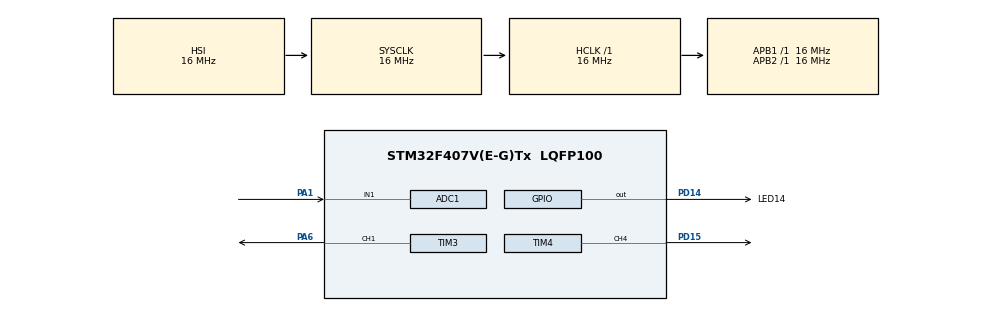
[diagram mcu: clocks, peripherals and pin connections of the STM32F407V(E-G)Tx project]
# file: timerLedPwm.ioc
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Mcu.Family=STM32F4
RCC.CortexFreq_Value=16000000
ADC1.Rank-0\#ChannelRegularConversion=1
SH.S_TIM4_CH4.0=TIM4_CH4,PWM Generation4 CH4
ProjectManager.StackSize=0x400
TIM3.Pulse-PWM\ Generation1\ CH1=500
ProjectManager.TargetToolchain=STM32CubeIDE
TIM3.Period=999
TIM4.Prescaler=31999
RCC.LSE_VALUE=32768
PA1.Signal=ADCx_IN1
RCC.AHBFreq_Value=16000000
TIM3.Channel-PWM\ Generation1\ CH1=TIM_CHANNEL_1
ADC1.Channel-0\#ChannelRegularConversion=ADC_CHANNEL_1
RCC.HSE_VALUE=25000000
board=custom
RCC.VCOOutputFreq_Value=192000000
TIM4.Pulse-PWM\ Generation4\ CH4=500
NVIC.TIM3_IRQn=true\:0\:0\:false\:false\:true\:true\:true
RCC.APB2Freq_Value=16000000
TIM3.Prescaler=7
PD14.GPIO_Label=LED14
SH.S_TIM3_CH1.0=TIM3_CH1,PWM Generation1 CH1
TIM4.Period=999
Mcu.Name=STM32F407V(E-G)Tx
ADC1.SamplingTime-0\#ChannelRegularConversion=ADC_SAMPLETIME_3CYCLES
PD14.Signal=GPIO_Output
RCC.SYSCLKFreq_VALUE=16000000
Mcu.Package=LQFP100
PA6.Signal=S_TIM3_CH1
ADC1.master=1
ProjectManager.HeapSize=0x200
RCC.HSI_VALUE=16000000
NVIC.PriorityGroup=NVIC_PRIORITYGROUP_4
ADC1.NbrOfConversionFlag=1
SH.ADCx_IN1.0=ADC1_IN1,IN1
TIM4.Channel-PWM\ Generation4\ CH4=TIM_CHANNEL_4
NVIC.TIM4_IRQn=true\:0\:0\:false\:false\:true\:true\:true
RCC.APB1Freq_Value=16000000
PD15.Signal=S_TIM4_CH4

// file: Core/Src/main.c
/* USER CODE BEGIN Header */
/**
  ******************************************************************************
  * @file           : main.c
  * @brief          : Main program body
  ******************************************************************************
  * @attention
  *
  * <h2><center>&copy; Copyright (c) 2021 STMicroelectronics.
  * All rights reserved.</center></h2>
  *
  * This software component is licensed by ST under BSD 3-Clause license,
  * the "License"; You may not use this file except in compliance with the
  * License. You may obtain a copy of the License at:
  *                        opensource.org/licenses/BSD-3-Clause
  *
  ******************************************************************************
  */
/* USER CODE END Header */
#include "main.h"

ADC_HandleTypeDef hadc1;

TIM_HandleTypeDef htim3;
TIM_HandleTypeDef htim4;

void SystemClock_Config(void);
static void MX_GPIO_Init(void);
static void MX_TIM3_Init(void);
static void MX_TIM4_Init(void);
static void MX_ADC1_Init(void);

int main(void)
{

  /* MCU Configuration--------------------------------------------------------*/

  /* Reset of all peripherals, Initializes the Flash interface and the Systick. */
  HAL_Init();

  /* Configure the system clock */
  SystemClock_Config();

  /* Initialize all configured peripherals */
  MX_GPIO_Init();
  MX_TIM3_Init();
  MX_TIM4_Init();
  MX_ADC1_Init();
  /* USER CODE BEGIN 2 */
  HAL_TIM_PWM_Start_IT(&htim4, TIM_CHANNEL_4);
  /* USER CODE END 2 */

  /* Infinite loop */
  /* USER CODE BEGIN WHILE */
  while (1)
  {

   TIM4 -> CCR4 = 250; // 0.5 saniye yandı
   //Channel4 kullanıldığı için CCR4 kullanıldı

    /* USER CODE END WHILE */

  }
}

void SystemClock_Config(void)
{
  RCC_OscInitTypeDef RCC_OscInitStruct = {0};
  RCC_ClkInitTypeDef RCC_ClkInitStruct = {0};

  /** Configure the main internal regulator output voltage
  */
  __HAL_RCC_PWR_CLK_ENABLE();
  __HAL_PWR_VOLTAGESCALING_CONFIG(PWR_REGULATOR_VOLTAGE_SCALE1);
  /** Initializes the RCC Oscillators according to the specified parameters
  * in the RCC_OscInitTypeDef structure.
  */
  RCC_OscInitStruct.OscillatorType = RCC_OSCILLATORTYPE_HSI;
  RCC_OscInitStruct.HSIState = RCC_HSI_ON;
  RCC_OscInitStruct.HSICalibrationValue = RCC_HSICALIBRATION_DEFAULT;
  RCC_OscInitStruct.PLL.PLLState = RCC_PLL_NONE;
  if (HAL_RCC_OscConfig(&RCC_OscInitStruct) != HAL_OK)
  {
    Error_Handler();
  }
  /** Initializes the CPU, AHB and APB buses clocks
  */
  RCC_ClkInitStruct.ClockType = RCC_CLOCKTYPE_HCLK|RCC_CLOCKTYPE_SYSCLK
                              |RCC_CLOCKTYPE_PCLK1|RCC_CLOCKTYPE_PCLK2;
  RCC_ClkInitStruct.SYSCLKSource = RCC_SYSCLKSOURCE_HSI;
  RCC_ClkInitStruct.AHBCLKDivider = RCC_SYSCLK_DIV1;
  RCC_ClkInitStruct.APB1CLKDivider = RCC_HCLK_DIV1;
  RCC_ClkInitStruct.APB2CLKDivider = RCC_HCLK_DIV1;

  if (HAL_RCC_ClockConfig(&RCC_ClkInitStruct, FLASH_LATENCY_0) != HAL_OK)
  {
    Error_Handler();
  }
}

static void MX_ADC1_Init(void)
{

  ADC_ChannelConfTypeDef sConfig = {0};

  /** Configure the global features of the ADC (Clock, Resolution, Data Alignment and number of conversion)
  */
  hadc1.Instance = ADC1;
  hadc1.Init.ClockPrescaler = ADC_CLOCK_SYNC_PCLK_DIV2;
  hadc1.Init.Resolution = ADC_RESOLUTION_12B;
  hadc1.Init.ScanConvMode = DISABLE;
  hadc1.Init.ContinuousConvMode = DISABLE;
  hadc1.Init.DiscontinuousConvMode = DISABLE;
  hadc1.Init.ExternalTrigConvEdge = ADC_EXTERNALTRIGCONVEDGE_NONE;
  hadc1.Init.ExternalTrigConv = ADC_SOFTWARE_START;
  hadc1.Init.DataAlign = ADC_DATAALIGN_RIGHT;
  hadc1.Init.NbrOfConversion = 1;
  hadc1.Init.DMAContinuousRequests = DISABLE;
  hadc1.Init.EOCSelection = ADC_EOC_SINGLE_CONV;
  if (HAL_ADC_Init(&hadc1) != HAL_OK)
  {
    Error_Handler();
  }
  /** Configure for the selected ADC regular channel its corresponding rank in the sequencer and its sample time.
  */
  sConfig.Channel = ADC_CHANNEL_1;
  sConfig.Rank = 1;
  sConfig.SamplingTime = ADC_SAMPLETIME_3CYCLES;
  if (HAL_ADC_ConfigChannel(&hadc1, &sConfig) != HAL_OK)
  {
    Error_Handler();
  }

}

static void MX_TIM3_Init(void)
{

  TIM_MasterConfigTypeDef sMasterConfig = {0};
  TIM_OC_InitTypeDef sConfigOC = {0};

  htim3.Instance = TIM3;
  htim3.Init.Prescaler = 7;
  htim3.Init.CounterMode = TIM_COUNTERMODE_UP;
  htim3.Init.Period = 999;
  htim3.Init.ClockDivision = TIM_CLOCKDIVISION_DIV1;
  htim3.Init.AutoReloadPreload = TIM_AUTORELOAD_PRELOAD_DISABLE;
  if (HAL_TIM_PWM_Init(&htim3) != HAL_OK)
  {
    Error_Handler();
  }
  sMasterConfig.MasterOutputTrigger = TIM_TRGO_RESET;
  sMasterConfig.MasterSlaveMode = TIM_MASTERSLAVEMODE_DISABLE;
  if (HAL_TIMEx_MasterConfigSynchronization(&htim3, &sMasterConfig) != HAL_OK)
  {
    Error_Handler();
  }
  sConfigOC.OCMode = TIM_OCMODE_PWM1;
  sConfigOC.Pulse = 500;
  sConfigOC.OCPolarity = TIM_OCPOLARITY_HIGH;
  sConfigOC.OCFastMode = TIM_OCFAST_DISABLE;
  if (HAL_TIM_PWM_ConfigChannel(&htim3, &sConfigOC, TIM_CHANNEL_1) != HAL_OK)
  {
    Error_Handler();
  }
  HAL_TIM_MspPostInit(&htim3);

}

static void MX_TIM4_Init(void)
{

  TIM_MasterConfigTypeDef sMasterConfig = {0};
  TIM_OC_InitTypeDef sConfigOC = {0};

  htim4.Instance = TIM4;
  htim4.Init.Prescaler = 31999;
  htim4.Init.CounterMode = TIM_COUNTERMODE_UP;
  htim4.Init.Period = 999;
  htim4.Init.ClockDivision = TIM_CLOCKDIVISION_DIV1;
  htim4.Init.AutoReloadPreload = TIM_AUTORELOAD_PRELOAD_DISABLE;
  if (HAL_TIM_PWM_Init(&htim4) != HAL_OK)
  {
    Error_Handler();
  }
  sMasterConfig.MasterOutputTrigger = TIM_TRGO_RESET;
  sMasterConfig.MasterSlaveMode = TIM_MASTERSLAVEMODE_DISABLE;
  if (HAL_TIMEx_MasterConfigSynchronization(&htim4, &sMasterConfig) != HAL_OK)
  {
    Error_Handler();
  }
  sConfigOC.OCMode = TIM_OCMODE_PWM1;
  sConfigOC.Pulse = 500;
  sConfigOC.OCPolarity = TIM_OCPOLARITY_HIGH;
  sConfigOC.OCFastMode = TIM_OCFAST_DISABLE;
  if (HAL_TIM_PWM_ConfigChannel(&htim4, &sConfigOC, TIM_CHANNEL_4) != HAL_OK)
  {
    Error_Handler();
  }
  HAL_TIM_MspPostInit(&htim4);

}

static void MX_GPIO_Init(void)
{
  GPIO_InitTypeDef GPIO_InitStruct = {0};

  /* GPIO Ports Clock Enable */
  __HAL_RCC_GPIOA_CLK_ENABLE();
  __HAL_RCC_GPIOD_CLK_ENABLE();

  /*Configure GPIO pin Output Level */
  HAL_GPIO_WritePin(LED14_GPIO_Port, LED14_Pin, GPIO_PIN_RESET);

  /*Configure GPIO pin : LED14_Pin */
  GPIO_InitStruct.Pin = LED14_Pin;
  GPIO_InitStruct.Mode = GPIO_MODE_OUTPUT_PP;
  GPIO_InitStruct.Pull = GPIO_NOPULL;
  GPIO_InitStruct.Speed = GPIO_SPEED_FREQ_LOW;
  HAL_GPIO_Init(LED14_GPIO_Port, &GPIO_InitStruct);

}

void Error_Handler(void)
{
  __disable_irq();
  while (1)
  {
  }
}

/************************ (C) COPYRIGHT STMicroelectronics *****END OF FILE****/
